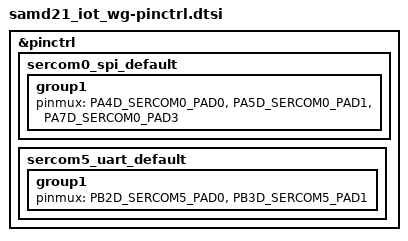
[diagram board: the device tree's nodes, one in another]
/*
 * SPDX-License-Identifier: Apache-2.0
 */

#include <dt-bindings/pinctrl/samd21-da1gXabcd-pinctrl.h>

&pinctrl {

    sercom0_spi_default: sercom0_spi_default {
        group1 {
            pinmux = <PA4D_SERCOM0_PAD0>,
                <PA5D_SERCOM0_PAD1>,
                <PA7D_SERCOM0_PAD3>;
        };
    };

//    sercom3_i2c_default: sercom3_i2c_default {
//        function = "I2C";
//        group = "SERCOM3";
//        pins = <22 23>;
//    };

    sercom5_uart_default: sercom5_uart_default {
        group1 {
            pinmux = <PB2D_SERCOM5_PAD0>,
                    <PB3D_SERCOM5_PAD1>;
        };
    };

};

